# CY8C5688AXI_LP099 register map
File version: 0.1
CY8C56LP
Registers are 8-bit, read-write, no defined reset value unless marked. A register's access mark holds for its fields unless they carry their own. Offsets are from the block's base; lines under a group give offsets from that group; [hi:lo] are bit positions; {n}, {i} and the like mark numbered series; 'fields as' and 'values as' point back to an identical list; <NAME> marks a mode.

## Memory map
0x00000000 FAN_STATUS_REG
0x00000000 DESULFATE_PWMGEN
0x00000000 ResistiveTouch_ADC_SAR — SAR ADC
0x00000000 PWM_ENABLE_REG
0x00000000 PPS_HI
0x00000000 PPS_LO
0x00000000 WATER_FLOW_COUNT
0x00000000 WATER_FLOW
0x00000000 WIFI_CS_OVERRIDE
0x00000000 BACKLIGHT_PWMGEN
0x00000000 SPIS_MCU
0x00000000 I2C
0x00000000 RTC
0x00000000 UART
0x00000000 SENSOR_SELECT

## FAN_STATUS_REG
Base 0x00000000
0x4000646B FAN_STATUS_REG_STATUS_REG
0x4000648B FAN_STATUS_REG_MASK_REG
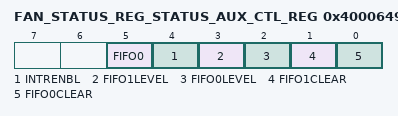
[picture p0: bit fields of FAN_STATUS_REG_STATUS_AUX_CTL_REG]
0x4000649B FAN_STATUS_REG_STATUS_AUX_CTL_REG
  [5] FIFO0 — FIFO0 clear
    1=ENABLED (Enable counter); 0=DISABLED (Disable counter)
  [4] INTRENBL — Enables or disables the Interrupt
    1=ENABLED (Interrupt enabled); 0=DISABLED (Interrupt disabled)
  [3] FIFO1LEVEL — FIFO level
    1=ENABLED (FIFO LVL: input mode: FIFO at least 1/2 empty; output mode: FIFO at least 1/2 full); 0=DISABLED (FIFO LVL: input mode: FIFO not full; output mode: FIFO not empty)
  [2] FIFO0LEVEL — FIFO level
    values as FIFO1LEVEL
  [1] FIFO1CLEAR — FIFO clear
    1=ENABLED (Clear FIFO state); 0=DISABLED (Normal FIFO operation)
  [0] FIFO0CLEAR — FIFO clear
    values as FIFO1CLEAR

## DESULFATE_PWMGEN
Base 0x00000000
0x40006529 DESULFATE_PWMGEN_COMPARE_Reg_ — UDB.D0 - Assigned Compare Value
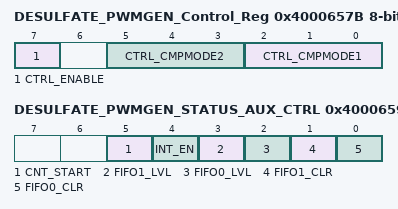
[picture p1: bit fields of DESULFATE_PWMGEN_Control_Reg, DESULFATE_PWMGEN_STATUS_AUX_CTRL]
0x4000657B DESULFATE_PWMGEN_Control_Reg — UDB Control Register - Assigned Control Register Value
  [7] CTRL_ENABLE — Enable the PWM
  [5:3] CTRL_CMPMODE2 — Compare mode 2
  [2:0] CTRL_CMPMODE1 — Compare mode 1
0x40006599 DESULFATE_PWMGEN_STATUS_AUX_CTRL — UDB Auxilliary Control Register
  [5] CNT_START — FIFO0 clear
    0=E_CNT_START0 (Disable counter); 1=E_CNT_START1 (Enable counter)
  [4] INT_EN
    0=E_INT_EN0 (Interrupt disabled); 1=E_INT_EN1 (Interrupt enabled)
  [3] FIFO1_LVL — FIFO level
    0=E_FIFO_LVL_0 (FIFO LVL: input mode: FIFO not full; output mode: FIFO not empty); 1=E_FIFO_LVL_1 (FIFO LVL: input mode: FIFO at least 1/2 empty; output mode: FIFO at least 1/2 full)
  [2] FIFO0_LVL — FIFO level
    values as FIFO1_LVL
  [1] FIFO1_CLR — FIFO1 clear
    0=E_FIFO_CLR_0 (Normal FIFO operation); 1=E_FIFO_CLR_1 (Clear FIFO state)
  [0] FIFO0_CLR — FIFO0 clear
    values as FIFO1_CLR

## ResistiveTouch_ADC_SAR — SAR ADC
Base 0x00000000
0x40004614 SAR_TR0 — SAR trim register
{0x40005900+i} SAR_CSR{i} (i=0..6) — SAR status and control register {i}
0x40005B20 SAR_SW0 — SAR Analog Routing Register 0
{0x40005B20+i} SAR_SW{i} (i=2..4) — SAR Analog Routing Register {i}
0x40005B26 SAR_SW6 — SAR Analog Routing Register 6
0x40005B27 SAR_CLK — SAR Clock Selection Register
0x40005BA0 SAR_WRK 16-bit — SAR working register

## PWM_ENABLE_REG
Base 0x00000000
0x40006479 PWM_ENABLE_REG_CONTROL_REG

## PPS_HI
Base 0x00000000
0x4000640C PPS_HI_COUNTER 16-bit — UDB.A0 - Current Counter Value
0x4000642C PPS_HI_PERIOD 16-bit — UDB.D0 - Assigned Period
0x4000643C PPS_HI_COMPARE 16-bit — UDB.D1 - Assigned Compare Value
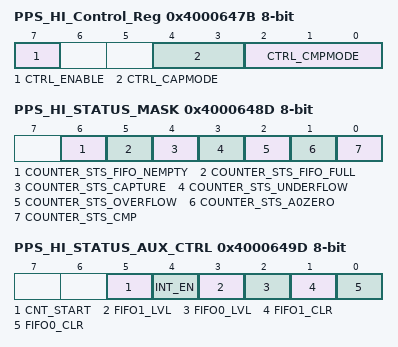
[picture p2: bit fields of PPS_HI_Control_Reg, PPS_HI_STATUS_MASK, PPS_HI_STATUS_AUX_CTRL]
0x4000647B PPS_HI_Control_Reg — UDB Control Register - Assigned Control Register Value
  [7] CTRL_ENABLE — Enable Counter
  [4:3] CTRL_CAPMODE — Capture mode
  [2:0] CTRL_CMPMODE — Compare mode
0x4000648D PPS_HI_STATUS_MASK — UDB Status bits Interrupt Mask Enable Register
  [6] COUNTER_STS_FIFO_NEMPTY — FIFO Not Empty Status
  [5] COUNTER_STS_FIFO_FULL — FIFO Full Status
  [4] COUNTER_STS_CAPTURE — Capture Status
  [3] COUNTER_STS_UNDERFLOW — Underflow status
  [2] COUNTER_STS_OVERFLOW — Overflow status
  [1] COUNTER_STS_A0ZERO — A0 Zero ouput status
  [0] COUNTER_STS_CMP — Compare output status
0x4000649D PPS_HI_STATUS_AUX_CTRL — UDB Auxilliary Control Register
  [5] CNT_START — FIFO0 clear
    0=E_CNT_START0 (Disable counter); 1=E_CNT_START1 (Enable counter)
  [4] INT_EN
    0=E_INT_EN0 (Interrupt disabled); 1=E_INT_EN1 (Interrupt enabled)
  [3] FIFO1_LVL — FIFO level
    0=E_FIFO_LVL_0 (FIFO LVL: input mode: FIFO not full; output mode: FIFO not empty); 1=E_FIFO_LVL_1 (FIFO LVL: input mode: FIFO at least 1/2 empty; output mode: FIFO at least 1/2 full)
  [2] FIFO0_LVL — FIFO level
    values as FIFO1_LVL
  [1] FIFO1_CLR — FIFO1 clear
    0=E_FIFO_CLR_0 (Normal FIFO operation); 1=E_FIFO_CLR_1 (Clear FIFO state)
  [0] FIFO0_CLR — FIFO0 clear
    values as FIFO1_CLR
